VERSION ""

NS_ :

BS_:

BU_: TempMonitor

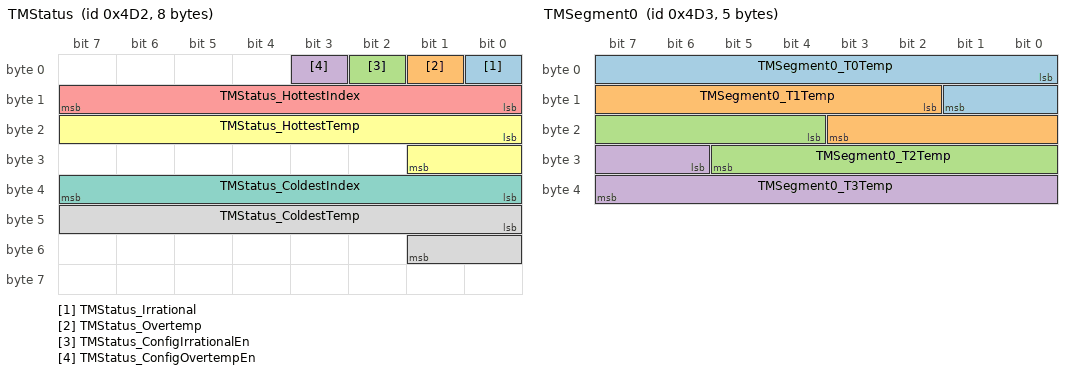
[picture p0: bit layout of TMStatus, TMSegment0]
BO_ 1234 TMStatus: 8 TempMonitor
 SG_ TMStatus_Irrational : 0|1@1+ (1,0) [0|1] "" Vector__XXX
 SG_ TMStatus_Overtemp : 1|1@1+ (1,0) [0|1] "" Vector__XXX
 SG_ TMStatus_ConfigIrrationalEn : 2|1@1+ (1,0) [0|1] "" Vector_XXX
 SG_ TMStatus_ConfigOvertempEn : 3|1@1+ (1,0) [0|1] "" Vector_XXX
 SG_ TMStatus_HottestIndex : 8|8@1+ (1,0) [0|23] "" Vector__XXX
 SG_ TMStatus_HottestTemp : 16|10@1+ (0.1,0) [0|0] "" Vector__XXX
 SG_ TMStatus_ColdestIndex : 32|8@1+ (1,0) [0|23] "" Vector__XXX
 SG_ TMStatus_ColdestTemp : 40|10@1+ (0.1,0) [0|0] "" Vector__XXX

BO_ 1235 TMSegment0: 5 TempMonitor
 SG_ TMSegment0_T0Temp : 0|10@1+ (0.1,0) [0|0] "" Vector__XXX
 SG_ TMSegment0_T1Temp : 10|10@1+ (0.1,0) [0|0] "" Vector__XXX
 SG_ TMSegment0_T2Temp : 20|10@1+ (0.1,0) [0|0] "" Vector__XXX
 SG_ TMSegment0_T3Temp : 30|10@1+ (0.1,0) [0|0] "" Vector__XXX

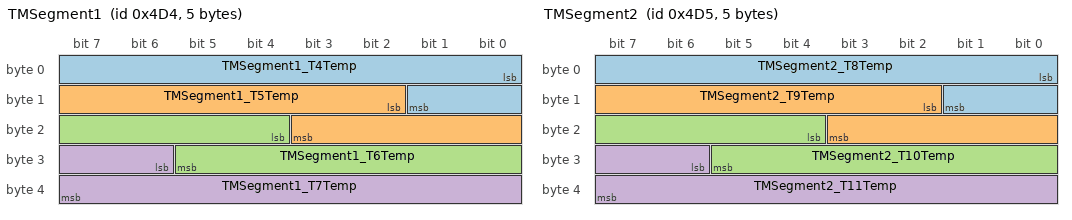
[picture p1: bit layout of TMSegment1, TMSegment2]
BO_ 1236 TMSegment1: 5 TempMonitor
 SG_ TMSegment1_T4Temp : 0|10@1+ (0.1,0) [0|0] "" Vector__XXX
 SG_ TMSegment1_T5Temp : 10|10@1+ (0.1,0) [0|0] "" Vector__XXX
 SG_ TMSegment1_T6Temp : 20|10@1+ (0.1,0) [0|0] "" Vector__XXX
 SG_ TMSegment1_T7Temp : 30|10@1+ (0.1,0) [0|0] "" Vector__XXX

BO_ 1237 TMSegment2: 5 TempMonitor
 SG_ TMSegment2_T8Temp : 0|10@1+ (0.1,0) [0|0] "" Vector__XXX
 SG_ TMSegment2_T9Temp : 10|10@1+ (0.1,0) [0|0] "" Vector__XXX
 SG_ TMSegment2_T10Temp : 20|10@1+ (0.1,0) [0|0] "" Vector__XXX
 SG_ TMSegment2_T11Temp : 30|10@1+ (0.1,0) [0|0] "" Vector__XXX

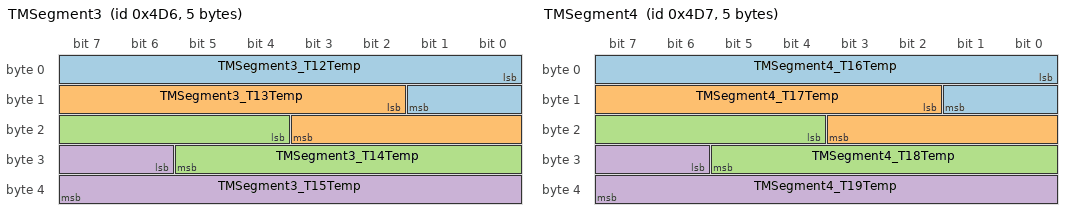
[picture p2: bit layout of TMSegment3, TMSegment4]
BO_ 1238 TMSegment3: 5 TempMonitor
 SG_ TMSegment3_T12Temp : 0|10@1+ (0.1,0) [0|0] "" Vector__XXX
 SG_ TMSegment3_T13Temp : 10|10@1+ (0.1,0) [0|0] "" Vector__XXX
 SG_ TMSegment3_T14Temp : 20|10@1+ (0.1,0) [0|0] "" Vector__XXX
 SG_ TMSegment3_T15Temp : 30|10@1+ (0.1,0) [0|0] "" Vector__XXX

BO_ 1239 TMSegment4: 5 TempMonitor
 SG_ TMSegment4_T16Temp : 0|10@1+ (0.1,0) [0|0] "" Vector__XXX
 SG_ TMSegment4_T17Temp : 10|10@1+ (0.1,0) [0|0] "" Vector__XXX
 SG_ TMSegment4_T18Temp : 20|10@1+ (0.1,0) [0|0] "" Vector__XXX
 SG_ TMSegment4_T19Temp : 30|10@1+ (0.1,0) [0|0] "" Vector__XXX

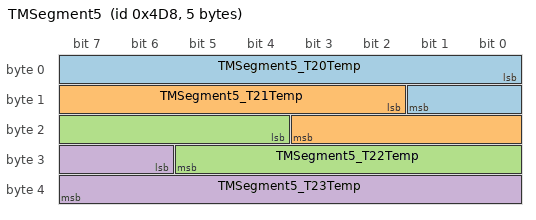
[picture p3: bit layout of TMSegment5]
BO_ 1240 TMSegment5: 5 TempMonitor
 SG_ TMSegment5_T20Temp : 0|10@1+ (0.1,0) [0|0] "" Vector__XXX
 SG_ TMSegment5_T21Temp : 10|10@1+ (0.1,0) [0|0] "" Vector__XXX
 SG_ TMSegment5_T22Temp : 20|10@1+ (0.1,0) [0|0] "" Vector__XXX
 SG_ TMSegment5_T23Temp : 30|10@1+ (0.1,0) [0|0] "" Vector__XXX
